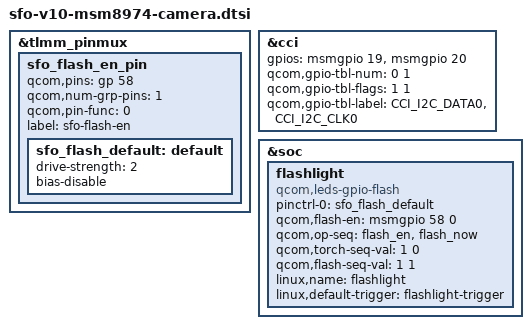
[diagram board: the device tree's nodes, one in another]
/*
 * Copyright (c) 2012-2013, The Linux Foundation. All rights reserved.
 *
 * This program is free software; you can redistribute it and/or modify
 * it under the terms of the GNU General Public License version 2 and
 * only version 2 as published by the Free Software Foundation.
 *
 * This program is distributed in the hope that it will be useful,
 * but WITHOUT ANY WARRANTY; without even the implied warranty of
 * MERCHANTABILITY or FITNESS FOR A PARTICULAR PURPOSE.  See the
 * GNU General Public License for more details.
 */

&tlmm_pinmux {
	sfo_flash_en_pin {
		qcom,pins = <&gp 58>;
		qcom,num-grp-pins = <1>;
		qcom,pin-func = <0>;
		label = "sfo-flash-en";

		sfo_flash_default: default {
			drive-strength = <2>;
			bias-disable;
		};
	};
};

&cci {
	gpios = <&msmgpio 19 0>,
		<&msmgpio 20 0>;
	qcom,gpio-tbl-num = <0 1>;
	qcom,gpio-tbl-flags = <1 1>;
	qcom,gpio-tbl-label = "CCI_I2C_DATA0",
			      "CCI_I2C_CLK0";
};

&soc {
	flashlight {
		compatible = "qcom,leds-gpio-flash";
		status = "okay";
		pinctrl-names = "flash_default";
		pinctrl-0 = <&sfo_flash_default>;
		qcom,flash-en = <&msmgpio 58 0>;
		qcom,op-seq = "flash_en", "flash_now";
		qcom,torch-seq-val = <1 0>;
		qcom,flash-seq-val = <1 1>;
		linux,name = "flashlight";
		linux,default-trigger = "flashlight-trigger";
	};
};
